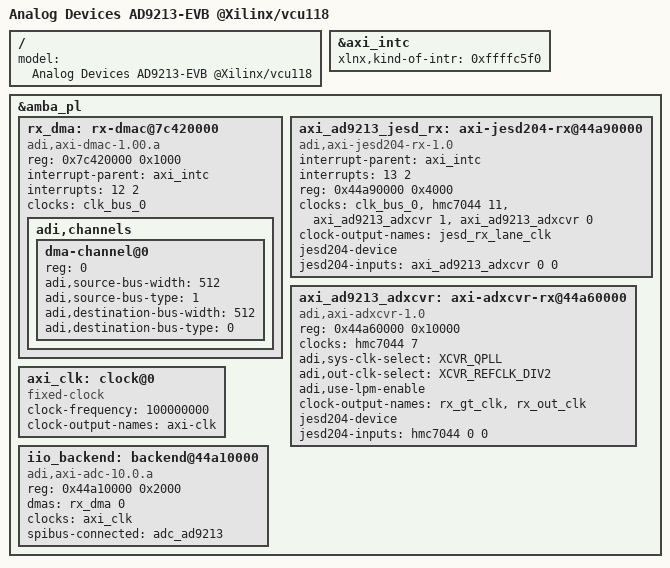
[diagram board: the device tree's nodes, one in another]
// SPDX-License-Identifier: GPL-2.0
/*
 * Analog Devices AD9213 ANALOG-TO-DIGITAL CONVERTER
 *
 * hdl_project: <ad9213_evb/vcu118>
 * board_revision: <>
 *
 * Copyright (C) 2023 Analog Devices Inc.
 */

/dts-v1/;

#include "vcu118.dtsi"
#include <dt-bindings/jesd204/adxcvr.h>

#define fmc_i2c fmcp_hspc_iic
#define fmc_spi axi_spi

/ {
	model = "Analog Devices AD9213-EVB @Xilinx/vcu118";
};

&axi_intc {
	xlnx,kind-of-intr = <0xffffc5f0>;
};

&amba_pl {

	rx_dma: rx-dmac@7c420000 {
		#dma-cells = <1>;
		compatible = "adi,axi-dmac-1.00.a";
		reg = <0x7c420000 0x1000>;
		#clock-cells = <0>;
		interrupt-parent = <&axi_intc>;
		interrupts = <12 2>;
		clocks = <&clk_bus_0>;

		adi,channels {
			#size-cells = <0>;
			#address-cells = <1>;

			dma-channel@0 {
				reg = <0>;
				adi,source-bus-width = <512>;
				adi,source-bus-type = <1>;
				adi,destination-bus-width = <512>;
				adi,destination-bus-type = <0>;
			};
		};
	};

	axi_ad9213_jesd_rx: axi-jesd204-rx@44a90000 {
		compatible = "adi,axi-jesd204-rx-1.0";
		interrupt-parent = <&axi_intc>;
		interrupts = <13 2>;
		reg = <0x44a90000 0x4000>;
		clocks = <&clk_bus_0>, <&hmc7044 11>, <&axi_ad9213_adxcvr 1>, <&axi_ad9213_adxcvr 0>;
		clock-names = "s_axi_aclk", "device_clk", "link_clk", "lane_clk";
		#clock-cells = <0>;
		clock-output-names = "jesd_rx_lane_clk";

		jesd204-device;
		#jesd204-cells = <2>;
		jesd204-inputs = <&axi_ad9213_adxcvr 0 0>;
	};

	axi_ad9213_adxcvr: axi-adxcvr-rx@44a60000 {
		#address-cells = <1>;
		#size-cells = <0>;
		compatible = "adi,axi-adxcvr-1.0";
		reg = <0x44a60000 0x10000>;
		clocks = <&hmc7044 7>;
		clock-names = "conv";

		adi,sys-clk-select = <XCVR_QPLL>;
		adi,out-clk-select = <XCVR_REFCLK_DIV2>; /* not used */
		adi,use-lpm-enable;

		#clock-cells = <1>;
		clock-output-names = "rx_gt_clk", "rx_out_clk";

		jesd204-device;
		#jesd204-cells = <2>;
		jesd204-inputs = <&hmc7044 0 0>;
	};

	axi_clk: clock@0 {
		compatible = "fixed-clock";
		clock-frequency = <100000000>;
		clock-output-names = "axi-clk";
		#clock-cells = <0>;
	};

	iio_backend: backend@44a10000{
		reg = <0x44a10000 0x2000>;
		compatible = "adi,axi-adc-10.0.a";
		dmas = <&rx_dma 0>;
		dma-names = "rx";
		clocks = <&axi_clk>;
		spibus-connected = <&adc_ad9213>;
	};
};

#include "adi-ad9213-evb.dtsi"
